# GD32A72_A74x register map
File version: 1.0
CPU: CM7 r2p1, little endian, MPU, FPU, DSP, 4 interrupt priority bits
Registers are 32-bit, read-write, reset 0x0 unless marked. A register's access mark holds for its fields unless they carry their own. Offsets are from the block's base; [hi:lo] are bit positions; {n}, {i} and the like mark numbered series.

## STCM — Self-test control module
Base 0x40025000
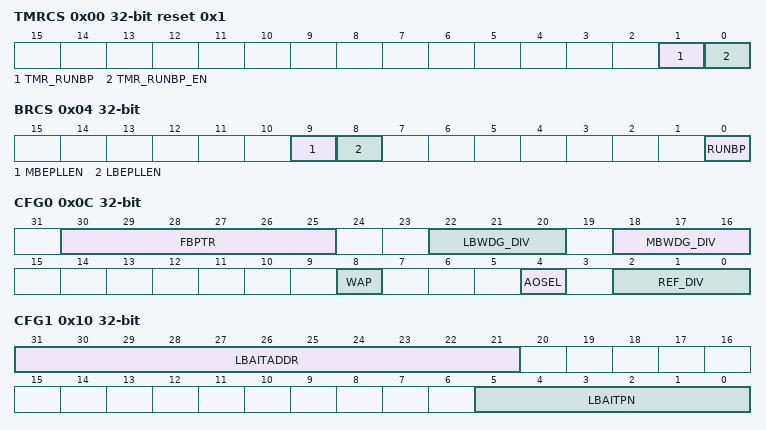
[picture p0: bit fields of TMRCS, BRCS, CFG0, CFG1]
0x00 TMRCS reset 0x1 — TMR control and status register
  [1] TMR_RUNBP — TMR (Triple-Modular Redundancy) state of run BIST phase
  [0] TMR_RUNBP_EN — TMR (Triple-Modular Redundancy) run BIST phase enable
0x04 BRCS — BIST running control and status register
  [9] MBEPLLEN — MBIST executed with PLL enabled
  [8] LBEPLLEN — LBIST executed with PLL enabled
  [0] RUNBP — Run BIST phase
0x08 WPK wo — Write protection key register
  [31:0] WPK — STCM write protection key
0x0C CFG0 — Configuration register 0
  [30:25] FBPTR — First BIST pointer
  [22:20] LBWDG_DIV — LBIST watchdog clock divider
  [18:16] MBWDG_DIV — MBIST watchdog clock divider
  [8] WAP — Write access protection
  [4] AOSEL — RAM or ROM selection
  [2:0] REF_DIV — Reference clock divider
0x10 CFG1 — Configuration register 1
  [31:21] LBAITADDR — The first AIT packet address of executing LBIST during phase
  [5:0] LBAITPN — The AIT packet number of executing LBIST during phase
0x14 LBWDGT reset 0xFFFF — LBIST watchdog timer register
  [31:0] LBWDGT — LBIST watchdog timer
0x18 MBWDGT reset 0xFFFF — MBIST watchdog timer register
  [31:0] MBWDGT — MBIST watch dog timer
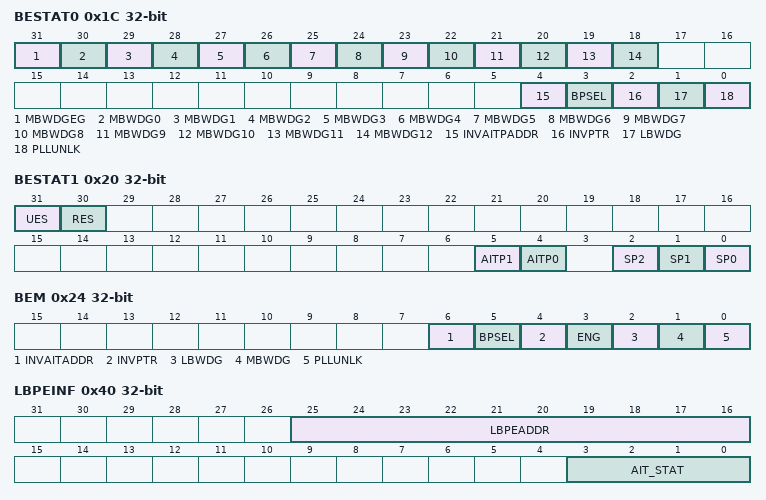
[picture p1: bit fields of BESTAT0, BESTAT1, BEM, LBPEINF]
0x1C BESTAT0 ro — BIST error state register 0
  [31] MBWDGEG — MBIST watchdog global error state
  [30-n] MBWDG{n} (n=0..12) — MBIST partition {n} watchdog error state
  [4] INVAITPADDR — Invalid AIT packet address error state
  [3] BPSEL — BIST phase select error state
  [2] INVPTR — Invalid LBIST pointer error state
  [1] LBWDG — LBIST watchdog error state
  [0] PLLUNLK — PLL unlock error state
0x20 BESTAT1 access per field — BIST error state register 1
  [31] UES rw — Unrecoverable error state
  [30] RES rw — Recoverable error state
  [5] AITP1 ro — AIT protocol error state1
  [4] AITP0 ro — AIT protocol error state 0
  [2] SP2 ro — SMART protocol error state 2
  [1] SP1 ro — SMART protocol error state 1
  [0] SP0 ro — SMART protocol error state 0
0x24 BEM — BIST error mapping register
  [6] INVAITADDR — Invalid AIT address error mapping
  [5] BPSEL — BIST patition selection error mapping
  [4] INVPTR — Invalid BIST pointer error mapping
  [3] ENG — Engine unrecoverable error mapping
  [2] LBWDG — LBIST watchdog error mapping
  [1] MBWDG — MBIST watchdog error mapping
  [0] PLLUNLK — PLL unlock error mapping
0x28 BINTVL — BIST interval register
  [31:0] INTVL — BIST interval, number of HCLK cycles between BISTs execution
0x30 LBCNTSTAMP — LBIST count stamp register
  [7:0] LB_CNT_STRAP — LBIST AIT engine inner timeout count strap
0x34 LBPSTAT ro — LBIST phase state register
  [1:0] LBP — LBIST phase state
0x38 LBPEF ro — LBIST phase end flag
  [1:0] LBPEF
0x3C LBPEM — LBIST phase error mapping register
  [0] LBP — LBIST phase unreconverable error mapping
0x40 LBPEINF ro — LBIST phase error information register
  [25:16] LBPEADDR — LBIST phase0 error address
  [3:0] AIT_STAT — These bits stored the state of AIT when LBIST execution result is failed or timeout
0x44 LBAITINTVL — LBIST AIT interval register
  [31:0] INTVL — AIT packets interval
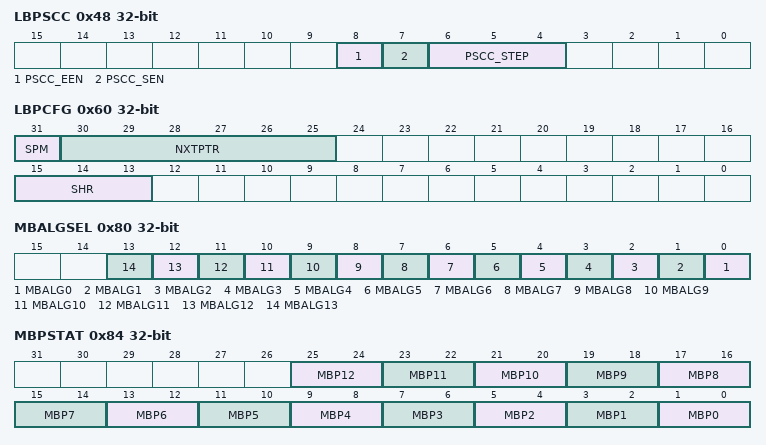
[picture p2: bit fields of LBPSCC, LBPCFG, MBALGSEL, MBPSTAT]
0x48 LBPSCC — LBIST peripheral shift clock control register
  [8] PSCC_EEN — Peripheral shift clock control end enable
  [7] PSCC_SEN — Peripheral shift clock control start enable
  [6:4] PSCC_STEP — Peripheral shift clock control step size
0x60 LBPCFG — LBIST phase configuration register
  [31] SPM — Serial / parallel mode
  [30:25] NXTPTR — Next LBIST or MBIST pointer
  [15:13] SHR — Shift rate
0x80 MBALGSEL — MBIST algorithm selection register
  [n] MBALG{n} (n=0..13) — MBIST algorithm {n} selection
0x84 MBPSTAT ro — MBIST phase state register
  [2n+1:2n] MBP{n} (n=0..12) — MBIST partition {n} state
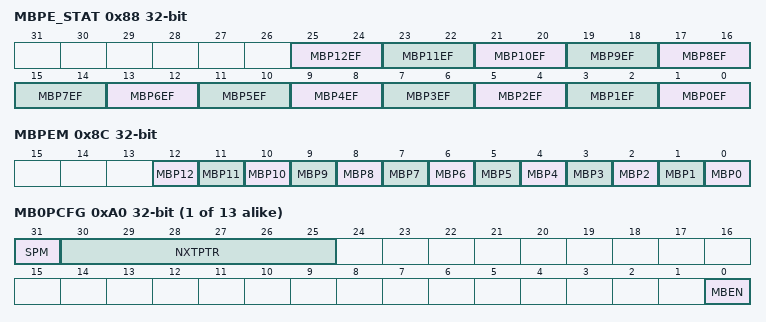
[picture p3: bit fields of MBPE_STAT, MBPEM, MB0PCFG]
0x88 MBPE_STAT ro — MBIST phase end state register
  [2n+1:2n] MBP{n}EF (n=0..12) — MBIST partition end flag {n}
0x8C MBPEM — MBIST phase error mapping register
  [n] MBP{n} (n=0..12) — mbist partition {n} unrecoverable error mapping
0x90 MBLAUNCH — MBIST phase launch register
  [2:0] MBLAUNCH — MBIST launch configuration
{0xA0+4i} MB{i}PCFG (i=0..12) — MBIST{i} phase configuration register
  [31] SPM — Serial/parallel mode
  [30:25] NXTPTR — Next LBIST or MBIST pointer
  [0] MBEN — MBIST enable
